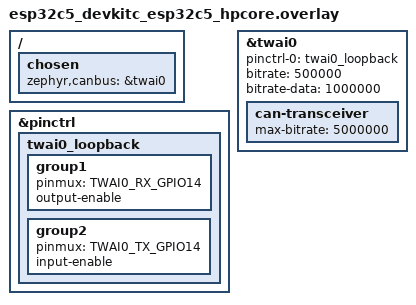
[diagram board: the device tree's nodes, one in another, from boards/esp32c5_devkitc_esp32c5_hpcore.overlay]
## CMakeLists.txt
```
# SPDX-License-Identifier: Apache-2.0

cmake_minimum_required(VERSION 3.28.0)
find_package(Zephyr REQUIRED HINTS $ENV{ZEPHYR_BASE})
project(integration)

target_sources(app PRIVATE src/common.c)
target_sources(app PRIVATE src/classic.c)
target_sources(app PRIVATE src/transceiver.c)
target_sources(app PRIVATE src/utilities.c)
target_sources_ifdef(CONFIG_CAN_FD_MODE app PRIVATE src/canfd.c)
target_sources_ifdef(CONFIG_CAN_STATS app PRIVATE src/stats.c)
target_sources_ifdef(CONFIG_PM_DEVICE app PRIVATE src/powermgmt.c)
target_sources_ifdef(CONFIG_PM app PRIVATE src/pm.c)
```

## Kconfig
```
# SPDX-License-Identifier: Apache-2.0

mainmenu "CAN Api test"

source "Kconfig.zephyr"

config CAN_TEST_MODE_LOOPBACK
    bool "Use Loopback mode for test"
    default y
    help
      Set the CAN controller into loopback mode to run the test

config CAN_TEST_MODE_LISTENONLY
   bool "Use Listenonly mode for test"
   default n
   help
     Set the CAN controller into listenonly mode to run the test
```

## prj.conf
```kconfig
CONFIG_CAN=y
CONFIG_CAN_FD_MODE=y
CONFIG_CAN_MANUAL_RECOVERY_MODE=y
CONFIG_STATS=y
CONFIG_CAN_STATS=y
CONFIG_TEST_USERSPACE=y
CONFIG_ZTEST=y
# Needed by test_add_rx_filter_msgq_dynamic, which expects a kernel oops
CONFIG_ZTEST_FATAL_HOOK=y
CONFIG_HEAP_MEM_POOL_SIZE=512
# Global default settings assign both the ZTest thread and the
# system worker queue to the same cooperative priority. Relying
# solely on the system worker queue for concurrency management
# can lead to unwanted interference between the two threads,
# causing the test to report its expected sequence of system
# events as an error. This situation will be avoided by moving
# the ZTest thread to the highest priority preemptive thread.
CONFIG_ZTEST_THREAD_PRIORITY=0
# The canfd test suite may be skipped
CONFIG_ZTEST_VERIFY_RUN_ALL=n
```

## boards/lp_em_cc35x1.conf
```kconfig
CONFIG_CAN_TI_CC35XX=y

CONFIG_I2S=n

CONFIG_SPI=n
CONFIG_SPI_SHELL=n
CONFIG_SPI_CC35XX=n

CONFIG_I2C=n
CONFIG_I2C_CC35XX=n
CONFIG_I2C_SHELL=n
CONFIG_SENSOR=n
CONFIG_SENSOR_SHELL=n
CONFIG_LM75=n
CONFIG_BMA4XX=n

CONFIG_ADC=n
CONFIG_ADC_CC35XX=n
CONFIG_ADC_SHELL=n

CONFIG_CAN_FD_MODE=n
```

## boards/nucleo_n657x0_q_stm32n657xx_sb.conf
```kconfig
# SPDX-FileCopyrightText: Copyright The Zephyr Project Contributors
# SPDX-License-Identifier: Apache-2.0

CONFIG_TEST_USERSPACE=n
```

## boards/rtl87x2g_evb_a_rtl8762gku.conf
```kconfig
# Copyright (c) 2026, Realtek Semiconductor Corporation
# SPDX-License-Identifier: Apache-2.0

CONFIG_CAN_FD_MODE=n
```

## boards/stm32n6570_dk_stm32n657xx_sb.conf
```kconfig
CONFIG_TEST_USERSPACE=n
```

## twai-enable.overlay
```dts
/*
 * Copyright (c) 2022 Martin Jäger <martin@libre.solar>
 *
 * SPDX-License-Identifier: Apache-2.0
 */

/* Enable CAN bus */
&twai {
	pinctrl-0 = <&twai_default>;
	pinctrl-names = "default";
	status = "okay";

	can-transceiver {
		max-bitrate = <1000000>;
	};
};

&pinctrl {
	twai_default: twai_default {
		group1 {
			pinmux = <TWAI_RX_GPIO5>;
			output-enable;	/* enable internal loopback */
		};

		group2 {
			pinmux = <TWAI_TX_GPIO5>;
			input-enable;	/* enable internal loopback */
		};
	};
};
```

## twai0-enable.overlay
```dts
/*
 * Copyright (c) 2026 Espressif Systems (Shanghai) Co., Ltd.
 *
 * SPDX-License-Identifier: Apache-2.0
 */

&twai0 {
	status = "okay";
	pinctrl-0 = <&twai0_loopback>;
	pinctrl-names = "default";
};

&pinctrl {
	twai0_loopback: twai0_loopback {
		group1 {
			pinmux = <TWAI0_RX_GPIO5>;
			output-enable;	/* enable internal loopback */
		};

		group2 {
			pinmux = <TWAI0_TX_GPIO5>;
			input-enable;	/* enable internal loopback */
		};
	};
};
```

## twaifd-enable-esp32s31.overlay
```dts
/*
 * Copyright (c) 2026 Espressif Systems (Shanghai) Co., Ltd.
 *
 * SPDX-License-Identifier: Apache-2.0
 */

&twai0 {
	status = "okay";
	pinctrl-0 = <&twai0_loopback>;
	pinctrl-names = "default";
};

&pinctrl {
	twai0_loopback: twai0_loopback {
		group1 {
			pinmux = <TWAI0_RX_GPIO44>;
			output-enable;	/* enable internal loopback */
		};

		group2 {
			pinmux = <TWAI0_TX_GPIO44>;
			input-enable;	/* enable internal loopback */
		};
	};
};
```

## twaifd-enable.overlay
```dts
/*
 * Copyright (c) 2026 Espressif Systems (Shanghai) Co., Ltd.
 *
 * SPDX-License-Identifier: Apache-2.0
 */

&twai0 {
	pinctrl-0 = <&twai0_loopback>;
	pinctrl-names = "default";
	status = "okay";
};

&pinctrl {
	twai0_loopback: twai0_loopback {
		group1 {
			pinmux = <TWAI0_RX_GPIO14>;
			output-enable;	/* enable internal loopback */
		};

		group2 {
			pinmux = <TWAI0_TX_GPIO14>;
			input-enable;	/* enable internal loopback */
		};
	};
};
```

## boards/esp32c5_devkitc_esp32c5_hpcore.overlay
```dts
/*
 * Copyright (c) 2026 Espressif Systems (Shanghai) Co., Ltd.
 *
 * SPDX-License-Identifier: Apache-2.0
 */

#include <zephyr/dt-bindings/pinctrl/esp-pinctrl-common.h>
#include <zephyr/dt-bindings/pinctrl/esp32c5-pinctrl.h>
#include <zephyr/dt-bindings/pinctrl/esp32c5-gpio-sigmap.h>

/ {
	chosen {
		zephyr,canbus = &twai0;
	};
};

&pinctrl {
	/*
	 * Override the board default: route TWAI0 TX and RX to the same
	 * GPIO14 so internal loopback mode can exercise the full protocol
	 * engine without an external transceiver. output-enable on the RX
	 * pinmux and input-enable on the TX pinmux keep the pin
	 * bidirectional after both apply_state() passes.
	 */
	twai0_loopback: twai0_loopback {
		group1 {
			pinmux = <TWAI0_RX_GPIO14>;
			output-enable;
		};

		group2 {
			pinmux = <TWAI0_TX_GPIO14>;
			input-enable;
		};
	};
};

&twai0 {
	status = "okay";
	pinctrl-0 = <&twai0_loopback>;
	pinctrl-names = "default";
	bitrate = <500000>;
	bitrate-data = <1000000>;

	can-transceiver {
		max-bitrate = <5000000>;
	};
};
```

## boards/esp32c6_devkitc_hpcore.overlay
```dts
/*
 * Copyright (c) 2025 Espressif Systems (Shanghai) Co., Ltd.
 *
 * SPDX-License-Identifier: Apache-2.0
 */

/* Enable CAN bus */
&twai0 {
	status = "okay";
	pinctrl-0 = <&twai_default>;
	pinctrl-names = "default";

	can-transceiver {
		max-bitrate = <1000000>;
	};
};

&pinctrl {
	twai_default: twai_default {
		group1 {
			pinmux = <TWAI0_RX_GPIO5>;
			output-enable;	/* enable internal loopback */
		};

		group2 {
			pinmux = <TWAI0_TX_GPIO5>;
			input-enable;	/* enable internal loopback */
		};
	};
};
```

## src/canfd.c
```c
/*
 * Copyright (c) 2022 Vestas Wind Systems A/S
 * Copyright (c) 2019 Alexander Wachter
 *
 * SPDX-License-Identifier: Apache-2.0
 */

#include <zephyr/drivers/can.h>
#include <zephyr/ztest.h>

#include "common.h"

/**
 * @addtogroup t_can_driver
 * @{
 * @defgroup t_can_canfd test_can_canfd
 * @}
 */

static void tx_std_callback_1(const struct device *dev, int error, void *user_data)
{
	const struct can_frame *frame = user_data;

	k_sem_give(&tx_callback_sem);

	zassert_equal(dev, can_dev, "CAN device does not match");
	zassert_equal(frame->id, TEST_CAN_STD_ID_1, "ID does not match");
}

static void tx_std_callback_2(const struct device *dev, int error, void *user_data)
{
	const struct can_frame *frame = user_data;

	k_sem_give(&tx_callback_sem);

	zassert_equal(dev, can_dev, "CAN device does not match");
	zassert_equal(frame->id, TEST_CAN_STD_ID_2, "ID does not match");
}

static void rx_std_callback_1(const struct device *dev, struct can_frame *frame, void *user_data)
{
	struct can_filter *filter = user_data;

	assert_frame_equal(frame, &test_std_frame_1, 0);
	zassert_equal(dev, can_dev, "CAN device does not match");
	zassert_equal_ptr(filter, &test_std_filter_1, "filter does not match");

	k_sem_give(&rx_callback_sem);
}

static void rx_std_callback_2(const struct device *dev, struct can_frame *frame, void *user_data)
{
	struct can_filter *filter = user_data;

	assert_frame_equal(frame, &test_std_frame_2, 0);
	zassert_equal(dev, can_dev, "CAN device does not match");
	zassert_equal_ptr(filter, &test_std_filter_2, "filter does not match");

	k_sem_give(&rx_callback_sem);
}

static void rx_std_callback_fd_1(const struct device *dev, struct can_frame *frame, void *user_data)
{
	struct can_filter *filter = user_data;

	assert_frame_equal(frame, &test_std_fdf_frame_1, 0);
	zassert_equal(dev, can_dev, "CAN device does not match");
	zassert_equal_ptr(filter, &test_std_filter_1, "filter does not match");

	k_sem_give(&rx_callback_sem);
}

static void rx_std_callback_fd_2(const struct device *dev, struct can_frame *frame, void *user_data)
{
	struct can_filter *filter = user_data;

	assert_frame_equal(frame, &test_std_fdf_frame_2, 0);
	zassert_equal(dev, can_dev, "CAN device does not match");
	zassert_equal_ptr(filter, &test_std_filter_2, "filter does not match");

	k_sem_give(&rx_callback_sem);
}

/**
 * @brief Send a CAN test frame with asserts.
 *
 * This function will block until the frame is transmitted or a test timeout
 * occurs.
 *
 * @param dev   Pointer to the device structure for the driver instance.
 * @param frame Pointer to the CAN frame to send.
 */
static void send_test_frame(const struct device *dev, const struct can_frame *frame)
{
	int err;

	err = can_send(dev, frame, TEST_SEND_TIMEOUT, NULL, NULL);
	zassert_not_equal(err, -EBUSY, "arbitration lost in loopback mode");
	zassert_ok(err, "failed to send frame (err %d)", err);
}

/**
 * @brief Send a CAN test frame with asserts.
 *
 * This function will block until the frame is queued or a test timeout
 * occurs.
 *
 * @param dev      Pointer to the device structure for the driver instance.
 * @param frame    Pointer to the CAN frame to send.
 * @param callback Transmit callback function.
 */
static void send_test_frame_nowait(const struct device *dev, const struct can_frame *frame,
				   can_tx_callback_t callback)
{
	int err;

	err = can_send(dev, frame, TEST_SEND_TIMEOUT, callback, (void *)frame);
	zassert_not_equal(err, -EBUSY, "arbitration lost in loopback mode");
	zassert_ok(err, "failed to send frame (err %d)", err);
}

/**
 * @brief Perform a send/receive test with a set of CAN ID filters and CAN frames.
 *
 * @param filter1 CAN filter 1
 * @param filter2 CAN filter 2
 * @param frame1  CAN frame 1
 * @param frame2  CAN frame 2
 */
static void send_receive(const struct can_filter *filter1, const struct can_filter *filter2,
			 const struct can_frame *frame1, const struct can_frame *frame2)
{
	struct can_frame frame_buffer;
	int filter_id_1;
	int filter_id_2;
	int err;

	filter_id_1 = can_common_add_rx_msgq(can_dev, filter1);
	send_test_frame(can_dev, frame1);

	err = k_msgq_get(&can_msgq, &frame_buffer, TEST_RECEIVE_TIMEOUT);
	zassert_ok(err, "receive timeout");

	assert_frame_equal(&frame_buffer, frame1, 0);
	can_remove_rx_filter(can_dev, filter_id_1);

	k_sem_reset(&tx_callback_sem);

	if ((frame1->flags & CAN_FRAME_FDF) != 0) {
		filter_id_1 = can_common_add_rx_filter(can_dev, filter1, rx_std_callback_fd_1);
	} else {
		filter_id_1 = can_common_add_rx_filter(can_dev, filter1, rx_std_callback_1);
	}

	if ((frame2->flags & CAN_FRAME_FDF) != 0) {
		filter_id_2 = can_common_add_rx_filter(can_dev, filter2, rx_std_callback_fd_2);
	} else {
		filter_id_2 = can_common_add_rx_filter(can_dev, filter2, rx_std_callback_2);
	}

	send_test_frame_nowait(can_dev, frame1, tx_std_callback_1);
	send_test_frame_nowait(can_dev, frame2, tx_std_callback_2);

	err = k_sem_take(&rx_callback_sem, TEST_RECEIVE_TIMEOUT);
	zassert_ok(err, "receive timeout");

	err = k_sem_take(&rx_callback_sem, TEST_RECEIVE_TIMEOUT);
	zassert_ok(err, "receive timeout");

	err = k_sem_take(&tx_callback_sem, TEST_SEND_TIMEOUT);
	zassert_ok(err, "missing TX callback");

	err = k_sem_take(&tx_callback_sem, TEST_SEND_TIMEOUT);
	zassert_ok(err, "missing TX callback");

	can_remove_rx_filter(can_dev, filter_id_1);
	can_remove_rx_filter(can_dev, filter_id_2);
}

/**
 * @brief Test getting the CAN controller capabilities.
 */
ZTEST(canfd, test_canfd_get_capabilities)
{
	can_mode_t cap;
	int err;

	err = can_get_capabilities(can_dev, &cap);
	zassert_ok(err, "failed to get CAN capabilities (err %d)", err);
	zassert_not_equal(cap & (CAN_MODE_LOOPBACK | CAN_MODE_FD), 0,
			  "CAN FD loopback mode not supported");
}

/**
 * @brief Test sending CAN FD frame with too big payload.
 */
ZTEST(canfd, test_send_fd_dlc_out_of_range)
{
	struct can_frame frame = {
		.flags = CAN_FRAME_FDF | CAN_FRAME_BRS,
		.id = TEST_CAN_STD_ID_1,
		.dlc = CANFD_MAX_DLC + 1U,
	};
	int err;

	Z_TEST_SKIP_IFNDEF(CONFIG_RUNTIME_ERROR_CHECKS);

	err = can_send(can_dev, &frame, TEST_SEND_TIMEOUT, NULL, NULL);
	zassert_equal(err, -EINVAL, "wrong error on sending invalid frame (err %d)", err);
}

/**
 * @brief Test error when CAN FD Error State Indicator (ESI) is set on transmit frame.
 *
 * CAN FD Error State Indicator (ESI) indicates that the transmitting node is in error-passive
 * state, but should never be set explicitly. Setting it is handled in the CAN controller hardware.
 */
ZTEST(canfd, test_send_fd_incorrect_esi)
{
	struct can_frame frame = {
		.flags = CAN_FRAME_FDF | CAN_FRAME_ESI,
		.id = TEST_CAN_STD_ID_1,
		.dlc = 0,
	};
	int err;

	err = can_send(can_dev, &frame, TEST_SEND_TIMEOUT, NULL, NULL);
	zassert_equal(err, -ENOTSUP, "wrong error on sending invalid frame (err %d)", err);
}

/**
 * @brief Test send/receive with standard (11-bit) CAN IDs and classic CAN frames.
 */
ZTEST(canfd, test_send_receive_classic)
{
	send_receive(&test_std_filter_1, &test_std_filter_2, &test_std_frame_1, &test_std_frame_2);
}

/**
 * @brief Test send/receive with standard (11-bit) CAN IDs and CAN FD frames.
 */
ZTEST(canfd, test_send_receive_fd)
{
	send_receive(&test_std_filter_1, &test_std_filter_2, &test_std_fdf_frame_1,
		     &test_std_fdf_frame_2);
}

/**
 * @brief Test send/receive with (11-bit) CAN IDs, mixed classic and CAN FD frames.
 */
ZTEST(canfd, test_send_receive_mixed)
{
	send_receive(&test_std_filter_1, &test_std_filter_2, &test_std_fdf_frame_1,
		     &test_std_frame_2);
}

/**
 * @brief Test that CAN RX filters are preserved through CAN controller mode changes.
 */
static void check_filters_preserved_between_modes(can_mode_t first, can_mode_t second)
{
	struct can_frame frame;
	enum can_state state;
	int filter_id_1;
	int filter_id_2;
	int err;

	/* Stop controller and set first mode */
	err = can_stop(can_dev);
	zassert_ok(err, "failed to stop CAN controller (err %d)", err);

	err = can_get_state(can_dev, &state, NULL);
	zassert_ok(err, "failed to get CAN state (err %d)", err);
	zassert_equal(state, CAN_STATE_STOPPED, "CAN controller not stopped");

	err = can_set_mode(can_dev, first | CAN_MODE_LOOPBACK);
	zassert_ok(err, "failed to set first loopback mode (err %d)", err);
	zassert_equal(first | CAN_MODE_LOOPBACK, can_get_mode(can_dev));

	err = can_start(can_dev);
	zassert_ok(err, "failed to start CAN controller (err %d)", err);

	/* Add classic CAN and CAN FD filter */
	filter_id_1 = can_common_add_rx_msgq(can_dev, &test_std_filter_1);
	filter_id_2 = can_common_add_rx_msgq(can_dev, &test_std_filter_2);

	/* Verify classic filter in first mode */
	send_test_frame(can_dev, &test_std_frame_1);
	err = k_msgq_get(&can_msgq, &frame, TEST_RECEIVE_TIMEOUT);
	zassert_ok(err, "receive timeout");
	assert_frame_equal(&frame, &test_std_frame_1, 0);

	if ((first & CAN_MODE_FD) != 0) {
		/* Verify CAN FD filter in first mode */
		send_test_frame(can_dev, &test_std_fdf_frame_2);
		err = k_msgq_get(&can_msgq, &frame, TEST_RECEIVE_TIMEOUT);
		zassert_ok(err, "receive timeout");
		assert_frame_equal(&frame, &test_std_fdf_frame_2, 0);
	}

	/* Stop controller and set second mode */
	err = can_stop(can_dev);
	zassert_ok(err, "failed to stop CAN controller (err %d)", err);

	err = can_get_state(can_dev, &state, NULL);
	zassert_ok(err, "failed to get CAN state (err %d)", err);
	zassert_equal(state, CAN_STATE_STOPPED, "CAN controller not stopped");

	err = can_set_mode(can_dev, second | CAN_MODE_LOOPBACK);
	zassert_ok(err, "failed to set second loopback mode (err %d)", err);
	zassert_equal(second | CAN_MODE_LOOPBACK, can_get_mode(can_dev));

	err = can_start(can_dev);
	zassert_ok(err, "failed to start CAN controller (err %d)", err);

	/* Verify classic filter in second mode */
	send_test_frame(can_dev, &test_std_frame_1);
	err = k_msgq_get(&can_msgq, &frame, TEST_RECEIVE_TIMEOUT);
	zassert_ok(err, "receive timeout");
	assert_frame_equal(&frame, &test_std_frame_1, 0);

	if ((second & CAN_MODE_FD) != 0) {
		/* Verify CAN FD filter in second mode */
		send_test_frame(can_dev, &test_std_fdf_frame_2);
		err = k_msgq_get(&can_msgq, &frame, TEST_RECEIVE_TIMEOUT);
		zassert_ok(err, "receive timeout");
		assert_frame_equal(&frame, &test_std_fdf_frame_2, 0);
	}

	/* Stop controller and restore CAN FD loopback mode */
	err = can_stop(can_dev);
	zassert_ok(err, "failed to stop CAN controller (err %d)", err);

	err = can_get_state(can_dev, &state, NULL);
	zassert_ok(err, "failed to get CAN state (err %d)", err);
	zassert_equal(state, CAN_STATE_STOPPED, "CAN controller not stopped");

	err = can_set_mode(can_dev, CAN_MODE_FD | CAN_MODE_LOOPBACK);
	zassert_ok(err, "failed to set loopback-mode (err %d)", err);
	zassert_equal(CAN_MODE_FD | CAN_MODE_LOOPBACK, can_get_mode(can_dev));

	err = can_start(can_dev);
	zassert_ok(err, "failed to start CAN controller (err %d)", err);

	can_remove_rx_filter(can_dev, filter_id_1);
	can_remove_rx_filter(can_dev, filter_id_2);
}

/**
 * @brief Test that CAN RX filters are preserved through CAN controller mode changes between classic
 * CAN and CAN FD.
 */
ZTEST_USER(canfd, test_filters_preserved_through_classic_to_fd_mode_change)
{
	check_filters_preserved_between_modes(CAN_MODE_NORMAL, CAN_MODE_FD);
}

/**
 * @brief Test that CAN RX filters are preserved through CAN controller mode changes between CAN FD
 * and classic CAN.
 */
ZTEST_USER(canfd, test_filters_preserved_through_fd_to_classic_mode_change)
{
	check_filters_preserved_between_modes(CAN_MODE_FD, CAN_MODE_NORMAL);
}

/**
 * @brief Test that the minimum timing values for the data phase can be set.
 */
ZTEST_USER(canfd, test_set_timing_data_min)
{
	int err;

	err = can_stop(can_dev);
	zassert_ok(err, "failed to stop CAN controller (err %d)", err);

	err = can_set_timing_data(can_dev, can_get_timing_data_min(can_dev));
	zassert_ok(err, "failed to set minimum timing data parameters (err %d)", err);

	err = can_set_bitrate_data(can_dev, CONFIG_CAN_DEFAULT_BITRATE_DATA);
	zassert_ok(err, "failed to restore default data bitrate");

	err = can_start(can_dev);
	zassert_ok(err, "failed to start CAN controller (err %d)", err);
}

/**
 * @brief Test setting a too low data phase bitrate.
 */
ZTEST_USER(canfd, test_set_bitrate_data_too_low)
{
	uint32_t min = can_get_bitrate_min(can_dev);
	int err;

	if (min == 0) {
		ztest_test_skip();
	}

	err = can_stop(can_dev);
	zassert_ok(err, "failed to stop CAN controller (err %d)", err);

	err = can_set_bitrate_data(can_dev, min - 1);
	zassert_equal(err, -ENOTSUP, "too low data phase bitrate accepted");

	err = can_set_bitrate_data(can_dev, CONFIG_CAN_DEFAULT_BITRATE_DATA);
	zassert_ok(err, "failed to restore default data bitrate");

	err = can_start(can_dev);
	zassert_ok(err, "failed to start CAN controller (err %d)", err);
}

/**
 * @brief Test setting a too high data phase bitrate.
 */
ZTEST_USER(canfd, test_set_bitrate_too_high)
{
	uint32_t max = can_get_bitrate_max(can_dev);
	int err;

	err = can_stop(can_dev);
	zassert_ok(err, "failed to stop CAN controller (err %d)", err);

	err = can_set_bitrate_data(can_dev, max + 1);
	zassert_equal(err, -ENOTSUP, "too high data phase bitrate accepted");

	err = can_start(can_dev);
	zassert_ok(err, "failed to start CAN controller (err %d)", err);
}

/**
 * @brief Test using an invalid sample point.
 */
ZTEST_USER(canfd, test_invalid_sample_point)
{
	struct can_timing timing;
	int err;

	err = can_calc_timing_data(can_dev, &timing, TEST_BITRATE_3, 1000);
	zassert_equal(err, -EINVAL, "invalid sample point of 100.0%% accepted (err %d)", err);
}

/**
 * @brief Test that the maximum timing values for the data phase can be set.
 */
ZTEST_USER(canfd, test_set_timing_data_max)
{
	int err;

	err = can_stop(can_dev);
	zassert_ok(err, "failed to stop CAN controller (err %d)", err);

	err = can_set_timing_data(can_dev, can_get_timing_data_max(can_dev));
	zassert_ok(err, "failed to set maximum timing data parameters (err %d)", err);

	err = can_set_bitrate_data(can_dev, CONFIG_CAN_DEFAULT_BITRATE_DATA);
	zassert_ok(err, "failed to restore default data bitrate");

	err = can_start(can_dev);
	zassert_ok(err, "failed to start CAN controller (err %d)", err);
}

/**
 * @brief Test setting data phase bitrate is not allowed while started.
 */
ZTEST_USER(canfd, test_set_bitrate_data_while_started)
{
	int err;

	err = can_set_bitrate_data(can_dev, TEST_BITRATE_3);
	zassert_not_equal(err, 0, "changed data bitrate while started");
	zassert_equal(err, -EBUSY, "wrong error return code (err %d)", err);
}

/**
 * @brief Test setting data phase timing is not allowed while started.
 */
ZTEST_USER(canfd, test_set_timing_data_while_started)
{
	struct can_timing timing = {0};
	int err;

	err = can_calc_timing_data(can_dev, &timing, TEST_BITRATE_3, TEST_SAMPLE_POINT_2);
	zassert_true(err >= 0, "failed to calculate data timing (err %d)", err);
	zassert_true(err <= CONFIG_CAN_SAMPLE_POINT_MARGIN, "sample point error %d too large", err);

	err = can_set_timing_data(can_dev, &timing);
	zassert_not_equal(err, 0, "changed data timing while started");
	zassert_equal(err, -EBUSY, "wrong error return code (err %d)", err);
}

static bool canfd_predicate(const void *state)
{
	can_mode_t cap;
	int err;

	ARG_UNUSED(state);

	if (!device_is_ready(can_dev)) {
		TC_PRINT("CAN device not ready");
		return false;
	}

	err = can_get_capabilities(can_dev, &cap);
	zassert_ok(err, "failed to get CAN controller capabilities (err %d)", err);

	if ((cap & CAN_MODE_FD) == 0) {
		return false;
	}

	return true;
}

void *canfd_setup(void)
{
	can_common_test_setup(CAN_MODE_LOOPBACK | CAN_MODE_FD);

	return NULL;
}

ZTEST_SUITE(canfd, canfd_predicate, canfd_setup, NULL, NULL, NULL);
```

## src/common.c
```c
/*
 * Copyright (c) 2022 Vestas Wind Systems A/S
 * Copyright (c) 2019 Alexander Wachter
 *
 * SPDX-License-Identifier: Apache-2.0
 */

#include <zephyr/drivers/can.h>
#include <zephyr/kernel.h>
#include <zephyr/ztest.h>

#include "common.h"

/**
 * @brief Global variables.
 */
ZTEST_DMEM const struct device *const can_dev = DEVICE_DT_GET(DT_CHOSEN(zephyr_canbus));
ZTEST_DMEM const struct device *const can_phy =
	DEVICE_DT_GET_OR_NULL(DT_PHANDLE(DT_CHOSEN(zephyr_canbus), phys));
struct k_sem rx_callback_sem;
struct k_sem tx_callback_sem;

CAN_MSGQ_DEFINE(can_msgq, 5);

/**
 * @brief Standard (11-bit) CAN ID frame 1.
 */
const struct can_frame test_std_frame_1 = {
	.flags = 0,
	.id = TEST_CAN_STD_ID_1,
	.dlc = 8,
	.data = {1, 2, 3, 4, 5, 6, 7, 8},
};

/**
 * @brief Standard (11-bit) CAN ID frame 2.
 */
const struct can_frame test_std_frame_2 = {
	.flags = 0,
	.id = TEST_CAN_STD_ID_2,
	.dlc = 8,
	.data = {1, 2, 3, 4, 5, 6, 7, 8},
};

/**
 * @brief Extended (29-bit) CAN ID frame 1.
 */
const struct can_frame test_ext_frame_1 = {
	.flags = CAN_FRAME_IDE,
	.id = TEST_CAN_EXT_ID_1,
	.dlc = 8,
	.data = {1, 2, 3, 4, 5, 6, 7, 8},
};

/**
 * @brief Extended (29-bit) CAN ID frame 1.
 */
const struct can_frame test_ext_frame_2 = {
	.flags = CAN_FRAME_IDE,
	.id = TEST_CAN_EXT_ID_2,
	.dlc = 8,
	.data = {1, 2, 3, 4, 5, 6, 7, 8},
};

/**
 * @brief Standard (11-bit) CAN ID RTR frame 1.
 */
const struct can_frame test_std_rtr_frame_1 = {
	.flags = CAN_FRAME_RTR,
	.id = TEST_CAN_STD_ID_1,
	.dlc = 0,
	.data = {0},
};

/**
 * @brief Extended (29-bit) CAN ID RTR frame 1.
 */
const struct can_frame test_ext_rtr_frame_1 = {
	.flags = CAN_FRAME_IDE | CAN_FRAME_RTR,
	.id = TEST_CAN_EXT_ID_1,
	.dlc = 0,
	.data = {0},
};

#ifdef CONFIG_CAN_FD_MODE
/**
 * @brief Standard (11-bit) CAN ID frame 1 with CAN FD payload.
 */
const struct can_frame test_std_fdf_frame_1 = {
	.flags = CAN_FRAME_FDF | CAN_FRAME_BRS,
	.id = TEST_CAN_STD_ID_1,
	.dlc = 0xf,
	.data = {1,  2,  3,  4,  5,  6,  7,  8,  9,  10, 11, 12, 13, 14, 15, 16,
		 17, 18, 19, 20, 21, 22, 23, 24, 25, 26, 27, 28, 29, 30, 31, 32,
		 33, 34, 35, 36, 37, 38, 39, 40, 41, 42, 43, 44, 45, 46, 47, 48,
		 49, 50, 51, 52, 53, 54, 55, 56, 57, 58, 59, 60, 61, 62, 63, 64},
};

/**
 * @brief Standard (11-bit) CAN ID frame 1 with CAN FD payload.
 */
const struct can_frame test_std_fdf_frame_2 = {
	.flags = CAN_FRAME_FDF | CAN_FRAME_BRS,
	.id = TEST_CAN_STD_ID_2,
	.dlc = 0xf,
	.data = {1,  2,  3,  4,  5,  6,  7,  8,  9,  10, 11, 12, 13, 14, 15, 16,
		 17, 18, 19, 20, 21, 22, 23, 24, 25, 26, 27, 28, 29, 30, 31, 32,
		 33, 34, 35, 36, 37, 38, 39, 40, 41, 42, 43, 44, 45, 46, 47, 48,
		 49, 50, 51, 52, 53, 54, 55, 56, 57, 58, 59, 60, 61, 62, 63, 64},
};
#endif /* CONFIG_CAN_FD_MODE */

/**
 * @brief Standard (11-bit) CAN ID filter 1. This filter matches
 * ``test_std_frame_1``.
 */
const struct can_filter test_std_filter_1 = {
	.flags = 0U,
	.id = TEST_CAN_STD_ID_1,
	.mask = CAN_STD_ID_MASK,
};

/**
 * @brief Standard (11-bit) CAN ID filter 2. This filter matches
 * ``test_std_frame_2``.
 */
const struct can_filter test_std_filter_2 = {
	.flags = 0U,
	.id = TEST_CAN_STD_ID_2,
	.mask = CAN_STD_ID_MASK,
};

/**
 * @brief Standard (11-bit) CAN ID masked filter 1. This filter matches
 * ``test_std_frame_1``.
 */
const struct can_filter test_std_masked_filter_1 = {
	.flags = 0U,
	.id = TEST_CAN_STD_MASK_ID_1,
	.mask = TEST_CAN_STD_MASK,
};

/**
 * @brief Standard (11-bit) CAN ID masked filter 2. This filter matches
 * ``test_std_frame_2``.
 */
const struct can_filter test_std_masked_filter_2 = {
	.flags = 0U,
	.id = TEST_CAN_STD_MASK_ID_2,
	.mask = TEST_CAN_STD_MASK,
};

/**
 * @brief Extended (29-bit) CAN ID filter 1. This filter matches
 * ``test_ext_frame_1``.
 */
const struct can_filter test_ext_filter_1 = {
	.flags = CAN_FILTER_IDE,
	.id = TEST_CAN_EXT_ID_1,
	.mask = CAN_EXT_ID_MASK,
};

/**
 * @brief Extended (29-bit) CAN ID filter 2. This filter matches
 * ``test_ext_frame_2``.
 */
const struct can_filter test_ext_filter_2 = {
	.flags = CAN_FILTER_IDE,
	.id = TEST_CAN_EXT_ID_2,
	.mask = CAN_EXT_ID_MASK,
};

/**
 * @brief Extended (29-bit) CAN ID masked filter 1. This filter matches
 * ``test_ext_frame_1``.
 */
const struct can_filter test_ext_masked_filter_1 = {
	.flags = CAN_FILTER_IDE,
	.id = TEST_CAN_EXT_MASK_ID_1,
	.mask = TEST_CAN_EXT_MASK,
};

/**
 * @brief Extended (29-bit) CAN ID masked filter 2. This filter matches
 * ``test_ext_frame_2``.
 */
const struct can_filter test_ext_masked_filter_2 = {
	.flags = CAN_FILTER_IDE,
	.id = TEST_CAN_EXT_MASK_ID_2,
	.mask = TEST_CAN_EXT_MASK,
};

/**
 * @brief Standard (11-bit) CAN ID filter. This filter matches
 * ``TEST_CAN_SOME_STD_ID``.
 */
const struct can_filter test_std_some_filter = {
	.flags = 0U,
	.id = TEST_CAN_SOME_STD_ID,
	.mask = CAN_STD_ID_MASK,
};

/**
 * @brief Assert that two CAN frames are equal given a CAN ID mask.
 *
 * @param frame1  First CAN frame.
 * @param frame2  Second CAN frame.
 * @param id_mask CAN ID mask.
 */
void assert_frame_equal(const struct can_frame *frame1, const struct can_frame *frame2,
			uint32_t id_mask)
{
	zassert_equal(frame1->flags, frame2->flags, "Flags do not match");
	zassert_equal(frame1->id | id_mask, frame2->id | id_mask, "ID does not match");
	zassert_equal(frame1->dlc, frame2->dlc, "DLC does not match");

	if ((frame1->flags & CAN_FRAME_RTR) == 0U) {
		zassert_mem_equal(frame1->data, frame2->data, can_dlc_to_bytes(frame1->dlc),
				  "Received data differ");
	}
}

int can_common_add_rx_msgq(const struct device *dev, const struct can_filter *filter)
{
	int filter_id;

	filter_id = can_add_rx_filter_msgq(dev, &can_msgq, filter);
	zassert_not_equal(filter_id, -ENOSPC, "no filters available");
	zassert_true(filter_id >= 0, "negative filter number");

	return filter_id;
}

int can_common_add_rx_filter(const struct device *dev, const struct can_filter *filter,
			     can_rx_callback_t callback)
{
	int filter_id;

	k_sem_reset(&rx_callback_sem);

	filter_id = can_add_rx_filter(dev, callback, (void *)filter, filter);
	zassert_not_equal(filter_id, -ENOSPC, "no filters available");
	zassert_true(filter_id >= 0, "negative filter number");

	return filter_id;
}

void can_common_test_setup(can_mode_t initial_mode)
{
	int err;

	k_sem_init(&rx_callback_sem, 0, 2);
	k_sem_init(&tx_callback_sem, 0, 2);

	k_object_access_grant(&can_msgq, k_current_get());
	k_object_access_grant(can_dev, k_current_get());

	zassert_true(device_is_ready(can_dev), "CAN device not ready");

	(void)can_stop(can_dev);

	err = can_set_mode(can_dev, initial_mode);
	zassert_ok(err, "failed to set initial mode (err %d)", err);
	zassert_equal(initial_mode, can_get_mode(can_dev));

	err = can_start(can_dev);
	zassert_ok(err, "failed to start CAN controller (err %d)", err);
}

void can_common_test_teardown(void)
{
	(void)can_stop(can_dev);
}
```

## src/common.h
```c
/*
 * Copyright (c) 2022 Vestas Wind Systems A/S
 * Copyright (c) 2019 Alexander Wachter
 *
 * SPDX-License-Identifier: Apache-2.0
 */

#include <zephyr/device.h>
#include <zephyr/drivers/can.h>
#include <zephyr/kernel.h>

/**
 * Test bitrates in bits/second.
 */
#define TEST_BITRATE_1 125000
#define TEST_BITRATE_2 250000
#define TEST_BITRATE_3 1000000

/**
 * Test sample points in per mille.
 */
#define TEST_SAMPLE_POINT 875
#define TEST_SAMPLE_POINT_2 750

/**
 * @brief Test timeouts.
 */
#define TEST_SEND_TIMEOUT    K_MSEC(100)
#define TEST_RECEIVE_TIMEOUT K_MSEC(100)
#define TEST_RECOVER_TIMEOUT K_MSEC(100)

/**
 * @brief Standard (11-bit) CAN IDs and masks used for testing.
 */
#define TEST_CAN_STD_ID_1      0x555
#define TEST_CAN_STD_ID_2      0x565
#define TEST_CAN_STD_MASK_ID_1 0x55A
#define TEST_CAN_STD_MASK_ID_2 0x56A
#define TEST_CAN_STD_MASK      0x7F0
#define TEST_CAN_SOME_STD_ID   0x123

/**
 * @brief Extended (29-bit) CAN IDs and masks used for testing.
 */
#define TEST_CAN_EXT_ID_1      0x15555555
#define TEST_CAN_EXT_ID_2      0x15555565
#define TEST_CAN_EXT_MASK_ID_1 0x1555555A
#define TEST_CAN_EXT_MASK_ID_2 0x1555556A
#define TEST_CAN_EXT_MASK      0x1FFFFFF0

/**
 * @brief Common variables.
 */
extern ZTEST_DMEM const struct device *const can_dev;
extern ZTEST_DMEM const struct device *const can_phy;
extern struct k_sem rx_callback_sem;
extern struct k_sem tx_callback_sem;
extern struct k_msgq can_msgq;

/**
 * @brief Standard (11-bit) CAN ID frame 1.
 */
extern const struct can_frame test_std_frame_1;

/**
 * @brief Standard (11-bit) CAN ID frame 2.
 */
extern const struct can_frame test_std_frame_2;

/**
 * @brief Extended (29-bit) CAN ID frame 1.
 */
extern const struct can_frame test_ext_frame_1;

/**
 * @brief Extended (29-bit) CAN ID frame 1.
 */
extern const struct can_frame test_ext_frame_2;

/**
 * @brief Standard (11-bit) CAN ID RTR frame 1.
 */
extern const struct can_frame test_std_rtr_frame_1;

/**
 * @brief Extended (29-bit) CAN ID RTR frame 1.
 */
extern const struct can_frame test_ext_rtr_frame_1;

#ifdef CONFIG_CAN_FD_MODE
/**
 * @brief Standard (11-bit) CAN ID frame 1 with CAN FD payload.
 */
extern const struct can_frame test_std_fdf_frame_1;

/**
 * @brief Standard (11-bit) CAN ID frame 2 with CAN FD payload.
 */
extern const struct can_frame test_std_fdf_frame_2;
#endif /* CONFIG_CAN_FD_MODE */

/**
 * @brief Standard (11-bit) CAN ID filter 1. This filter matches
 * ``test_std_frame_1`` and ``test_std_fdf_frame_1``.
 */
extern const struct can_filter test_std_filter_1;

/**
 * @brief Standard (11-bit) CAN ID filter 2. This filter matches
 * ``test_std_frame_2`` and ``test_std_fdf_frame_2``.
 */
extern const struct can_filter test_std_filter_2;

/**
 * @brief Standard (11-bit) CAN ID masked filter 1. This filter matches
 * ``test_std_frame_1``.
 */
extern const struct can_filter test_std_masked_filter_1;

/**
 * @brief Standard (11-bit) CAN ID masked filter 2. This filter matches
 * ``test_std_frame_2``.
 */
extern const struct can_filter test_std_masked_filter_2;

/**
 * @brief Extended (29-bit) CAN ID filter 1. This filter matches
 * ``test_ext_frame_1``.
 */
extern const struct can_filter test_ext_filter_1;

/**
 * @brief Extended (29-bit) CAN ID filter 2. This filter matches
 * ``test_ext_frame_2``.
 */
extern const struct can_filter test_ext_filter_2;

/**
 * @brief Extended (29-bit) CAN ID masked filter 1. This filter matches
 * ``test_ext_frame_1``.
 */
extern const struct can_filter test_ext_masked_filter_1;

/**
 * @brief Extended (29-bit) CAN ID masked filter 2. This filter matches
 * ``test_ext_frame_2``.
 */
extern const struct can_filter test_ext_masked_filter_2;

/**
 * @brief Standard (11-bit) CAN ID filter. This filter matches
 * ``TEST_CAN_SOME_STD_ID``.
 */
extern const struct can_filter test_std_some_filter;

/**
 * @brief Assert that two CAN frames are equal given a CAN ID mask.
 *
 * @param frame1  First CAN frame.
 * @param frame2  Second CAN frame.
 * @param id_mask CAN ID mask.
 */
void assert_frame_equal(const struct can_frame *frame1,
			const struct can_frame *frame2,
			uint32_t id_mask);

/**
 * @brief Add a CAN message queue with asserts.
 *
 * @param dev    Pointer to the device structure for the driver instance.
 * @param filter CAN filter for the CAN message queue.
 *
 * @return CAN filter ID.
 */
int can_common_add_rx_msgq(const struct device *dev, const struct can_filter *filter);

/**
 * @brief Add a CAN filter with asserts.
 *
 * @param dev      Pointer to the device structure for the driver instance.
 * @param filter   CAN filter.
 * @param callback Receive callback function.
 *
 * @return CAN filter ID.
 */
int can_common_add_rx_filter(const struct device *dev, const struct can_filter *filter,
			     can_rx_callback_t callback);

/**
 * @brief Common setup function for the CAN controller device under test.
 *
 * @param initial_mode Initial CAN controller operational mode.
 */
void can_common_test_setup(can_mode_t initial_mode);

/** Common teardown function for the CAN controller device under test. */
void can_common_test_teardown(void);
```

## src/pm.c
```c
/*
 * Copyright (c) 2026 Espressif Systems (Shanghai) Co., Ltd.
 *
 * SPDX-License-Identifier: Apache-2.0
 */

#include <zephyr/drivers/can.h>
#include <zephyr/kernel.h>
#include <zephyr/pm/pm.h>
#include <zephyr/pm/state.h>
#include <zephyr/sys/atomic.h>
#include <zephyr/ztest.h>

#include "common.h"

/**
 * @addtogroup t_can_driver
 * @{
 * @defgroup t_can_pm test_can_pm
 * @}
 */

/* Long enough for the idle thread to reach the power management policy. */
#define TEST_IDLE_WINDOW K_MSEC(100)

static atomic_t low_power_entries;

static void pm_state_entry(enum pm_state state)
{
	ARG_UNUSED(state);

	atomic_inc(&low_power_entries);
}

static struct pm_notifier test_pm_notifier = {
	.state_entry = pm_state_entry,
};

static void pm_tx_callback(const struct device *dev, int error, void *user_data)
{
	ARG_UNUSED(dev);
	ARG_UNUSED(user_data);

	zassert_equal(error, 0, "transmit failed after a low power state (err %d)", error);
	k_sem_give(&tx_callback_sem);
}

/**
 * @brief Idle for a while and report how many low power states were entered.
 */
static int idle_and_count_low_power_entries(void)
{
	atomic_clear(&low_power_entries);
	k_sleep(TEST_IDLE_WINDOW);

	return (int)atomic_get(&low_power_entries);
}

static void send_and_loopback_after_sleep(const struct can_frame *expected)
{
	struct can_frame frame;
	int err;

	k_sem_reset(&tx_callback_sem);

	err = can_send(can_dev, expected, TEST_SEND_TIMEOUT, pm_tx_callback, NULL);
	zassert_ok(err, "failed to queue frame after a low power state (err %d)", err);

	err = k_sem_take(&tx_callback_sem, TEST_SEND_TIMEOUT);
	zassert_ok(err, "transmit callback not called after a low power state");

	err = k_msgq_get(&can_msgq, &frame, TEST_RECEIVE_TIMEOUT);
	zassert_ok(err, "receive timeout after a low power state");

	assert_frame_equal(expected, &frame, 0);
}

/**
 * @brief Test that no low power state is entered while the CAN controller is started.
 */
ZTEST(can_pm, test_started_blocks_low_power_states)
{
	zassert_equal(idle_and_count_low_power_entries(), 0,
		      "entered a low power state while the CAN controller was started");
}

/**
 * @brief Test that stopping the CAN controller lets the system enter low power states again.
 */
ZTEST(can_pm, test_stopped_allows_low_power_states)
{
	int err;

	err = can_stop(can_dev);
	zassert_ok(err, "failed to stop CAN controller (err %d)", err);

	zassert_true(idle_and_count_low_power_entries() > 0,
		     "never entered a low power state with the CAN controller stopped");
}

/**
 * @brief Test that a start reporting -EALREADY keeps low power states blocked.
 */
ZTEST(can_pm, test_redundant_start_keeps_low_power_states_blocked)
{
	int err;

	err = can_start(can_dev);
	zassert_equal(err, -EALREADY, "starting a started CAN controller did not report -EALREADY");

	zassert_equal(idle_and_count_low_power_entries(), 0,
		      "entered a low power state after a redundant start");

	err = can_stop(can_dev);
	zassert_ok(err, "failed to stop CAN controller (err %d)", err);

	zassert_true(idle_and_count_low_power_entries() > 0,
		     "never entered a low power state after a redundant start and a stop");
}

/**
 * @brief Test that a stop reporting -EALREADY keeps low power states available.
 */
ZTEST(can_pm, test_redundant_stop_keeps_low_power_states_allowed)
{
	int err;

	err = can_stop(can_dev);
	zassert_ok(err, "failed to stop CAN controller (err %d)", err);

	err = can_stop(can_dev);
	zassert_equal(err, -EALREADY, "stopping a stopped CAN controller did not report -EALREADY");

	zassert_true(idle_and_count_low_power_entries() > 0,
		     "never entered a low power state after a redundant stop");
}

/**
 * @brief Test sending and receiving after a low power state without reconfiguring.
 */
ZTEST(can_pm, test_configuration_survives_low_power_state)
{
	int filter_id;
	int err;

	err = can_stop(can_dev);
	zassert_ok(err, "failed to stop CAN controller (err %d)", err);

	filter_id = can_common_add_rx_msgq(can_dev, &test_std_filter_1);

	zassert_true(idle_and_count_low_power_entries() > 0,
		     "never entered a low power state, nothing was verified");

	err = can_start(can_dev);
	zassert_ok(err, "failed to start CAN controller after a low power state (err %d)", err);

	send_and_loopback_after_sleep(&test_std_frame_1);

	can_remove_rx_filter(can_dev, filter_id);
}

#ifdef CONFIG_CAN_FD_MODE
/**
 * @brief Test that CAN FD timing still works after a low power state without reconfiguring.
 */
ZTEST(can_pm, test_fd_configuration_survives_low_power_state)
{
	can_mode_t caps = 0;
	int filter_id;
	int err;

	err = can_get_capabilities(can_dev, &caps);
	zassert_ok(err, "failed to get CAN capabilities (err %d)", err);
	if ((caps & CAN_MODE_FD) == 0) {
		ztest_test_skip();
		return;
	}

	err = can_stop(can_dev);
	zassert_ok(err, "failed to stop CAN controller (err %d)", err);

	err = can_set_mode(can_dev, CAN_MODE_LOOPBACK | CAN_MODE_FD);
	zassert_ok(err, "failed to set CAN FD loopback mode (err %d)", err);

	filter_id = can_common_add_rx_msgq(can_dev, &test_std_filter_1);

	zassert_true(idle_and_count_low_power_entries() > 0,
		     "never entered a low power state, nothing was verified");

	err = can_start(can_dev);
	zassert_ok(err, "failed to start CAN controller after a low power state (err %d)", err);

	send_and_loopback_after_sleep(&test_std_fdf_frame_1);

	can_remove_rx_filter(can_dev, filter_id);

	err = can_stop(can_dev);
	zassert_ok(err, "failed to stop CAN controller (err %d)", err);
	err = can_set_mode(can_dev, CAN_MODE_LOOPBACK);
	zassert_ok(err, "failed to restore loopback mode (err %d)", err);
}
#endif /* CONFIG_CAN_FD_MODE */

static bool can_pm_predicate(const void *state)
{
	const struct pm_state_info *states;
	uint8_t count;

	ARG_UNUSED(state);

	if (!device_is_ready(can_dev)) {
		TC_PRINT("CAN device not ready\n");
		return false;
	}

	count = pm_state_cpu_get_all(0U, &states);
	if (count == 0U) {
		TC_PRINT("no low power states defined for this platform\n");
		return false;
	}

	return true;
}

static void *can_pm_setup(void)
{
	can_common_test_setup(CAN_MODE_LOOPBACK);
	pm_notifier_register(&test_pm_notifier);

	return NULL;
}

static void can_pm_before(void *fixture)
{
	int err;

	ARG_UNUSED(fixture);

	/* Each test starts from a started controller, whatever the previous one left behind. */
	err = can_start(can_dev);
	if (err != -EALREADY) {
		zassert_ok(err, "failed to start CAN controller (err %d)", err);
	}
}

static void can_pm_teardown(void *fixture)
{
	ARG_UNUSED(fixture);

	pm_notifier_unregister(&test_pm_notifier);
}

ZTEST_SUITE(can_pm, can_pm_predicate, can_pm_setup, can_pm_before, NULL, can_pm_teardown);
```

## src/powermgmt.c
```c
/*
 * SPDX-FileCopyrightText: Copyright (c) 2026 Henrik Brix Andersen <henrik@brixandersen.dk>
 * SPDX-License-Identifier: Apache-2.0
 */

#include <zephyr/drivers/can.h>
#include <zephyr/pm/device.h>
#include <zephyr/pm/device_runtime.h>
#include <zephyr/ztest.h>

#include "common.h"

/**
 * @addtogroup t_can_driver
 * @{
 * @defgroup t_can_powermgmt test_can_powermgmt
 * @}
 */

/**
 * @brief Test suspending and resuming the CAN controller device.
 */
ZTEST(can_powermgmt, test_suspend_resume)
{
	enum pm_device_state pm_state;
	struct can_frame frame;
	int filter_id;
	int err;

	err = can_stop(can_dev);
	zassert_ok(err, "failed to stop CAN controller (err %d)", err);

	err = pm_device_action_run(can_dev, PM_DEVICE_ACTION_SUSPEND);
	zassert_ok(err, "failed to suspend CAN controller (err %d)", err);

	err = pm_device_state_get(can_dev, &pm_state);
	zassert_ok(err, "failed to get CAN controller power management state (err %d)", err);
	zassert_equal(pm_state, PM_DEVICE_STATE_SUSPENDED, "CAN controller not suspended (%s)",
		      pm_device_state_str(pm_state));

	err = pm_device_action_run(can_dev, PM_DEVICE_ACTION_RESUME);
	zassert_ok(err, "failed to resume CAN controller (err %d)", err);

	err = pm_device_state_get(can_dev, &pm_state);
	zassert_ok(err, "failed to get CAN controller power management state (err %d)", err);
	zassert_equal(pm_state, PM_DEVICE_STATE_ACTIVE, "CAN controller not active (%s)",
		      pm_device_state_str(pm_state));

	err = can_set_mode(can_dev, CAN_MODE_LOOPBACK);
	zassert_ok(err, "failed to set loopback mode (err %d)", err);
	zassert_equal(CAN_MODE_LOOPBACK, can_get_mode(can_dev));

	err = can_start(can_dev);
	zassert_ok(err, "failed to start CAN controller (err %d)", err);

	filter_id = can_common_add_rx_msgq(can_dev, &test_std_filter_1);

	err = can_send(can_dev, &test_std_frame_1, TEST_SEND_TIMEOUT, NULL, NULL);
	zassert_ok(err, "failed to send frame without data (err %d)", err);

	err = k_msgq_get(&can_msgq, &frame, TEST_RECEIVE_TIMEOUT);
	zassert_ok(err, "receive timeout");

	assert_frame_equal(&test_std_frame_1, &frame, 0);

	can_remove_rx_filter(can_dev, filter_id);
}

/**
 * @brief Test suspending the CAN controller device while started.
 */
ZTEST(can_powermgmt, test_suspend_while_started)
{
	int err;

	err = pm_device_action_run(can_dev, PM_DEVICE_ACTION_SUSPEND);
	zassert_equal(err, -EBUSY, "suspended CAN controller while started");
}

/**
 * @brief Test suspending the CAN controller device while RX filters are added.
 */
ZTEST(can_powermgmt, test_suspend_while_filters_added)
{
	int filter_id;
	int err;

	err = can_stop(can_dev);
	zassert_ok(err, "failed to stop CAN controller (err %d)", err);

	filter_id = can_add_rx_filter_msgq(can_dev, &can_msgq, &test_std_filter_1);
	zassert_not_equal(filter_id, -ENOSPC, "no filters available");
	zassert_true(filter_id >= 0, "negative filter number");

	err = pm_device_action_run(can_dev, PM_DEVICE_ACTION_SUSPEND);
	zassert_equal(err, -EBUSY, "suspended CAN controller while RX filters added");

	can_remove_rx_filter(can_dev, filter_id);

	err = can_start(can_dev);
	zassert_ok(err, "failed to start CAN controller (err %d)", err);
}

static bool can_powermgmt_predicate(const void *state)
{
	enum pm_device_state pm_state;
	int err;

	ARG_UNUSED(state);

	if (!device_is_ready(can_dev)) {
		TC_PRINT("CAN device not ready");
		return false;
	}

	if (pm_device_runtime_is_enabled(can_dev)) {
		TC_PRINT("CAN device uses runtime device power management");
		return false;
	}

	err = pm_device_state_get(can_dev, &pm_state);
	if (err == -ENOSYS) {
		TC_PRINT("CAN controller does not support device power management");
		return false;
	}

	return true;
}

void *can_powermgmt_setup(void)
{
	can_common_test_setup(CAN_MODE_LOOPBACK);

	return NULL;
}

ZTEST_SUITE(can_powermgmt, can_powermgmt_predicate, can_powermgmt_setup, NULL, NULL, NULL);
```

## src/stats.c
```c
/*
 * Copyright (c) 2023 Vestas Wind Systems A/S
 *
 * SPDX-License-Identifier: Apache-2.0
 */

#include <zephyr/drivers/can.h>
#include <zephyr/ztest.h>

#include "common.h"

/* Stats are cleared on every can_start/stop. */
#define EXPECTED  0

/**
 * @addtogroup t_driver_can
 * @{
 * @defgroup t_can_stats test_can_stats
 * @}
 */

/**
 * @brief Test that CAN statistics can be accessed from user mode threads.
 */
ZTEST_USER(can_stats, test_can_stats_accessors)
{
	uint32_t val;

	val = can_stats_get_bit_errors(can_dev);
	zassert_true(val == EXPECTED, "CAN bit errors are too high");
	val = can_stats_get_bit0_errors(can_dev);
	zassert_true(val == EXPECTED, "CAN bit0 errors are too high");
	val = can_stats_get_bit1_errors(can_dev);
	zassert_true(val == EXPECTED, "CAN bit1 errors are too high");
	val = can_stats_get_stuff_errors(can_dev);
	zassert_true(val == EXPECTED, "CAN stuff errors are too high");
	val = can_stats_get_crc_errors(can_dev);
	zassert_true(val == EXPECTED, "CAN crc errors are too high");
	val = can_stats_get_form_errors(can_dev);
	zassert_true(val == EXPECTED, "CAN form errors are too high");
	val = can_stats_get_ack_errors(can_dev);
	zassert_true(val == EXPECTED, "CAN ack errors are too high");
	val = can_stats_get_rx_overruns(can_dev);
	zassert_true(val == EXPECTED, "CAN rx overruns are too high");
}

void *can_stats_setup(void)
{
	k_object_access_grant(can_dev, k_current_get());

	zassert_true(device_is_ready(can_dev), "CAN device not ready");

	return NULL;
}

ZTEST_SUITE(can_stats, NULL, can_stats_setup, NULL, NULL, NULL);
```

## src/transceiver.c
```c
/*
 * Copyright (c) 2024 Vestas Wind Systems A/S
 *
 * SPDX-License-Identifier: Apache-2.0
 */

#include <zephyr/drivers/can.h>
#include <zephyr/ztest.h>

#include "common.h"

/**
 * @addtogroup t_can_driver
 * @{
 * @defgroup t_can_transceiver test_can_transceiver
 * @}
 */

/**
 * @brief Test getting CAN transceiver device pointer.
 */
ZTEST_USER(can_transceiver, test_get_transceiver)
{
	const struct device *phy = can_get_transceiver(can_dev);

	zassert_equal(phy, can_phy, "wrong CAN transceiver device pointer returned");
}

static bool can_transceiver_predicate(const void *state)
{
	ARG_UNUSED(state);

	if (!device_is_ready(can_dev)) {
		TC_PRINT("CAN device not ready");
		return false;
	}

	if (!device_is_ready(can_phy)) {
		TC_PRINT("CAN transceiver device not ready");
		return false;
	}

	return true;
}

void *can_transceiver_setup(void)
{
	k_object_access_grant(can_dev, k_current_get());
	k_object_access_grant(can_phy, k_current_get());

	zassert_true(device_is_ready(can_dev), "CAN device not ready");
	zassert_true(device_is_ready(can_phy), "CAN transceiver device not ready");

	return NULL;
}

ZTEST_SUITE(can_transceiver, can_transceiver_predicate, can_transceiver_setup, NULL, NULL, NULL);
```
